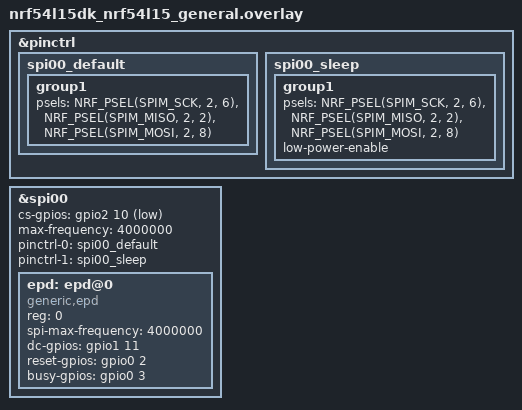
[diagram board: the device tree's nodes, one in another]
/*
 * Copyright (c) 2023 Nordic Semiconductor ASA
 *
 * SPDX-License-Identifier: Apache-2.0
 */

 &pinctrl {
	spi00_default: spi00_default {
		group1 {
			// nordic,drive-mode = <NRF_DRIVE_H0H1>;
			psels = <NRF_PSEL(SPIM_SCK, 2, 6)>,
			        <NRF_PSEL(SPIM_MISO, 2, 2)>,
			        <NRF_PSEL(SPIM_MOSI, 2, 8)>;
		};
	};

	spi00_sleep: spi00_sleep {
		group1 {
			psels = <NRF_PSEL(SPIM_SCK, 2, 6)>,
			        <NRF_PSEL(SPIM_MISO, 2, 2)>,
			        <NRF_PSEL(SPIM_MOSI, 2, 8)>;
			low-power-enable;
		};
	};

};

 &spi00 {
	cs-gpios = <&gpio2 10 GPIO_ACTIVE_LOW>;
	status="okay";
	max-frequency = < 4000000 >;
	pinctrl-0 = <&spi00_default>;
	pinctrl-1 = <&spi00_sleep>;

	epd: epd@0 {
		compatible = "generic,epd";
		reg = <0>;
		status = "okay";
		spi-max-frequency = <4000000>;
		dc-gpios = <&gpio1 11 GPIO_ACTIVE_HIGH>;        /* D9 EPD driver use raw instead of logical level */
		reset-gpios = <&gpio0 2 GPIO_ACTIVE_HIGH>;     /* D8 EPD driver use raw instead of logical level */
		busy-gpios = <&gpio0 3 GPIO_ACTIVE_HIGH>;      /* D7 EPD driver use raw instead of logical level */
	};
 };
